# PIC32MZ1025W104132 register map
Vendor: Microchip
Registers are 32-bit, read-write, no defined reset value unless marked. A register's access mark holds for its fields unless they carry their own. Addresses are absolute, and some are shared; only a register's first bit layout is shown; [hi:lo] are bit positions; {n}, {i} and the like mark numbered series.

## ADCHS2
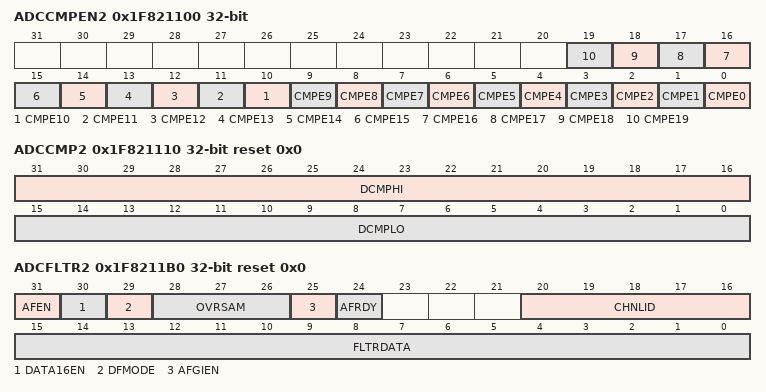
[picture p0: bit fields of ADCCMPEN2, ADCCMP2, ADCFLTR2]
0x1F821100 ADCCMPEN2 — (power-on value ------------xxxx0000000000000000)
  [n] CMPE{n} (n=0..19)
0x1F821110 ADCCMP2 reset 0x0
  [31:16] DCMPHI, [15:0] DCMPLO
0x1F8211B0 ADCFLTR2 reset 0x0
  [31] AFEN, [30] DATA16EN, [29] DFMODE, [28:26] OVRSAM, [25] AFGIEN, [24] AFRDY ro, [20:16] CHNLID, [15:0] FLTRDATA ro

## CAN1
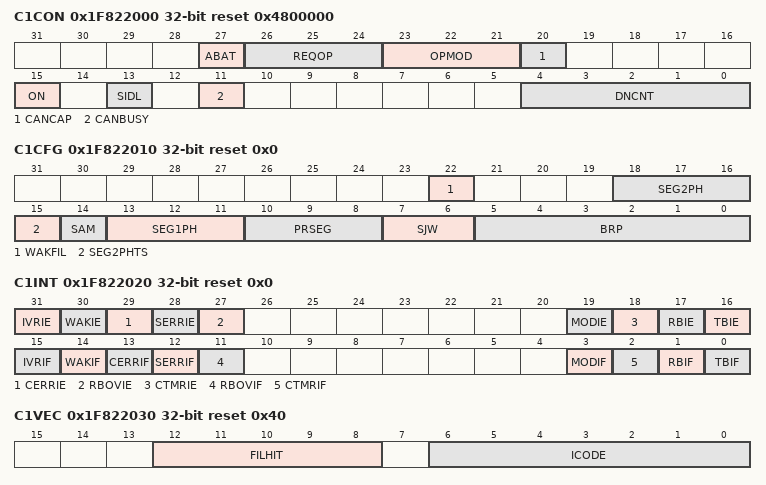
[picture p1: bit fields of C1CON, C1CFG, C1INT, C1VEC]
0x1F822000 C1CON reset 0x4800000
  [27] ABAT — (can only be set)
  [26:24] REQOP
  [23:21] OPMOD ro
  [20] CANCAP
  [15] ON
  [13] SIDL
  [11] CANBUSY ro
  [4:0] DNCNT
0x1F822010 C1CFG reset 0x0
  [22] WAKFIL, [18:16] SEG2PH, [15] SEG2PHTS, [14] SAM, [13:11] SEG1PH, [10:8] PRSEG, [7:6] SJW, [5:0] BRP
0x1F822020 C1INT reset 0x0
  [31] IVRIE, [30] WAKIE, [29] CERRIE, [28] SERRIE, [27] RBOVIE, [19] MODIE, [18] CTMRIE, [17] RBIE, [16] TBIE, [15] IVRIF, [14] WAKIF, [13] CERRIF, [12] SERRIF, [11] RBOVIF, [3] MODIF, [2] CTMRIF, [1] RBIF, [0] TBIF
0x1F822030 C1VEC ro reset 0x40
  [12:8] FILHIT, [6:0] ICODE
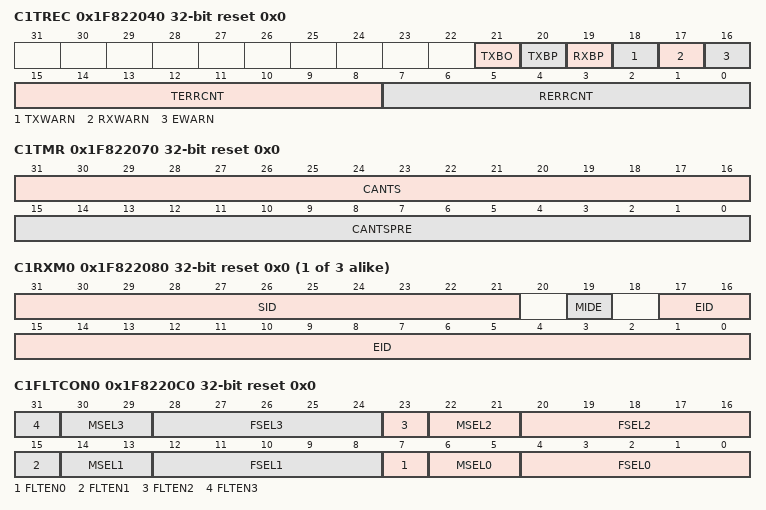
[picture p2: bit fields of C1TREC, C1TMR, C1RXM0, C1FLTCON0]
0x1F822040 C1TREC ro reset 0x0
  [21] TXBO, [20] TXBP, [19] RXBP, [18] TXWARN, [17] RXWARN, [16] EWARN, [15:8] TERRCNT, [7:0] RERRCNT
0x1F822050 C1FSTAT ro reset 0x0
  [31:0] FIFOIP
0x1F822060 C1RXOVF ro reset 0x0
  [31:0] RXOVF
0x1F822070 C1TMR reset 0x0
  [31:16] CANTS, [15:0] CANTSPRE
{0x1F822080+0x10*i} C1RXM{i} reset 0x0 (i=0..2)
  [31:21] SID, [19] MIDE, [17:0] EID
0x1F8220C0 C1FLTCON0 reset 0x0
  [8n+7] FLTEN{n} (n=0..3), [8n+6:8n+5] MSEL{n} (n=0..3), [8n+4:8n] FSEL{n} (n=0..3)
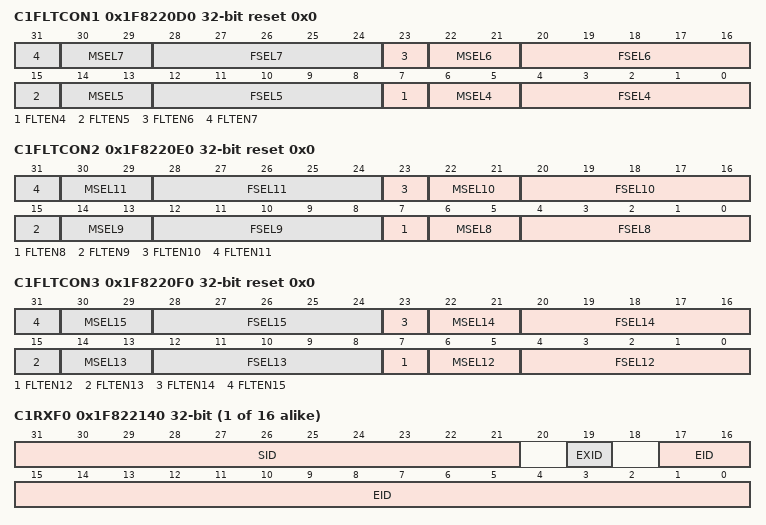
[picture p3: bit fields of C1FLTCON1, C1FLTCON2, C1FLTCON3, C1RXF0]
0x1F8220D0 C1FLTCON1 reset 0x0
  [8n-25] FLTEN{n} (n=4..7), [8n-26:8n-27] MSEL{n} (n=4..7), [8n-28:8n-32] FSEL{n} (n=4..7)
0x1F8220E0 C1FLTCON2 reset 0x0
  [8n-57] FLTEN{n} (n=8..11), [8n-58:8n-59] MSEL{n} (n=8..11), [8n-60:8n-64] FSEL{n} (n=8..11)
0x1F8220F0 C1FLTCON3 reset 0x0
  [8n-89] FLTEN{n} (n=12..15), [8n-90:8n-91] MSEL{n} (n=12..15), [8n-92:8n-96] FSEL{n} (n=12..15)
{0x1F822140+0x10*i} C1RXF{i} (i=0..15) — (power-on value xxxxxxxxxxx0x0xxxxxxxxxxxxxxxxxx)
  [31:21] SID, [19] EXID, [17:0] EID
0x1F822340 C1FIFOBA reset 0x0
  [31:2] FIFOBA
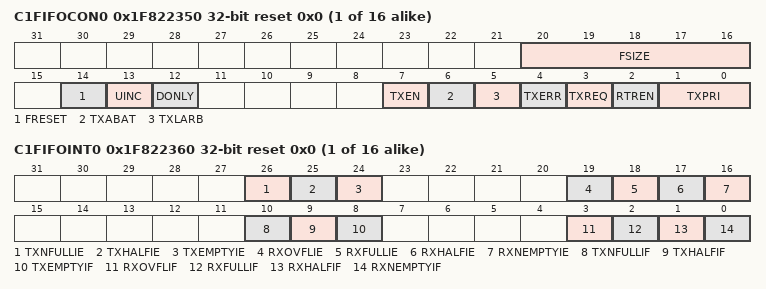
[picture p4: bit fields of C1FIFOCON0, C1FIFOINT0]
{0x1F822350+0x40*i} C1FIFOCON{i} reset 0x0 (i=0..15)
  [20:16] FSIZE, [14] FRESET, [13] UINC, [12] DONLY, [7] TXEN, [6] TXABAT, [5] TXLARB, [4] TXERR, [3] TXREQ, [2] RTREN, [1:0] TXPRI
{0x1F822360+0x40*i} C1FIFOINT{i} reset 0x0 (i=0..15)
  [26] TXNFULLIE, [25] TXHALFIE, [24] TXEMPTYIE, [19] RXOVFLIE, [18] RXFULLIE, [17] RXHALFIE, [16] RXNEMPTYIE, [10] TXNFULLIF ro, [9] TXHALFIF ro, [8] TXEMPTYIF ro, [3] RXOVFLIF, [2] RXFULLIF ro, [1] RXHALFIF ro, [0] RXNEMPTYIF ro
{0x1F822370+0x40*i} C1FIFOUA{i} ro (i=0..15) — (power-on value xxxxxxxxxxxxxxxxxxxxxxxxxxxxxx00)
  [31:2] FIFOUA
{0x1F822380+0x40*i} C1FIFOCI{i} ro reset 0x0 (i=0..15)
  [4:0] CFIFOCI

## CVD
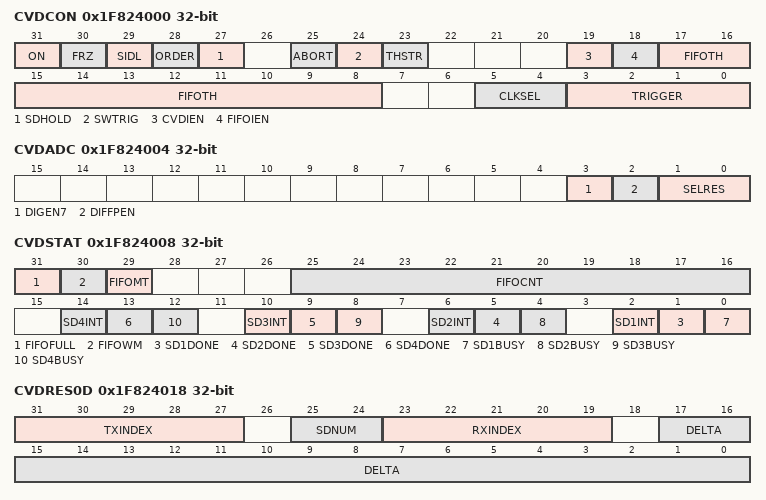
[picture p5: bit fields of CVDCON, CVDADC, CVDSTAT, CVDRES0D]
0x1F824000 CVDCON — (power-on value xxxxx-xxx---xxxxxxxxxxxx--xxxxxx)
  [31] ON, [30] FRZ, [29] SIDL, [28] ORDER, [27] SDHOLD, [25] ABORT, [24] SWTRIG, [23] THSTR, [19] CVDIEN, [18] FIFOIEN, [17:8] FIFOTH, [5:4] CLKSEL, [3:0] TRIGGER
0x1F824004 CVDADC — (power-on value ----------------------------xxxx)
  [3] DIGEN7, [2] DIFFPEN, [1:0] SELRES
0x1F824008 CVDSTAT — (power-on value xxx---xxxxxxxxxx-----------x-xxx)
  [31] FIFOFULL, [30] FIFOWM, [29] FIFOMT, [25:16] FIFOCNT, [4n-2] SD{n}INT (n=1..4), [4n-3] SD{n}DONE (n=1..4), [4n-4] SD{n}BUSY (n=1..4)
0x1F824010 CVDRES0H — (power-on value --------xxxxxxxxxxxxxxxxxxxxxxxx)
  [23:0] POS
0x1F824014 CVDRES0L — (power-on value --------xxxxxxxxxxxxxxxxxxxxxxxx)
  [23:0] NEG
0x1F824018 CVDRES0D — (power-on value xxxxx-xxxxxxx-xxxxxxxxxxxxxxxxxx)
  [31:27] TXINDEX, [25:24] SDNUM, [23:19] RXINDEX, [17:0] DELTA
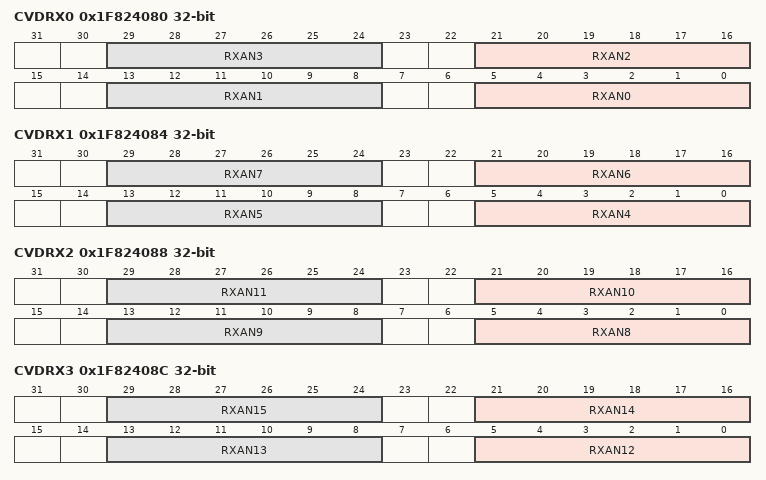
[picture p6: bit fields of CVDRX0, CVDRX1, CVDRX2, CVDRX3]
0x1F824080 CVDRX0 — (power-on value --xxxxxx--xxxxxx--xxxxxx--xxxxxx)
  [8n+5:8n] RXAN{n} (n=0..3)
0x1F824084 CVDRX1 — (power-on value --xxxxxx--xxxxxx--xxxxxx--xxxxxx)
  [8n-27:8n-32] RXAN{n} (n=4..7)
0x1F824088 CVDRX2 — (power-on value --xxxxxx--xxxxxx--xxxxxx--xxxxxx)
  [8n-59:8n-64] RXAN{n} (n=8..11)
0x1F82408C CVDRX3 — (power-on value --xxxxxx--xxxxxx--xxxxxx--xxxxxx)
  [8n-91:8n-96] RXAN{n} (n=12..15)
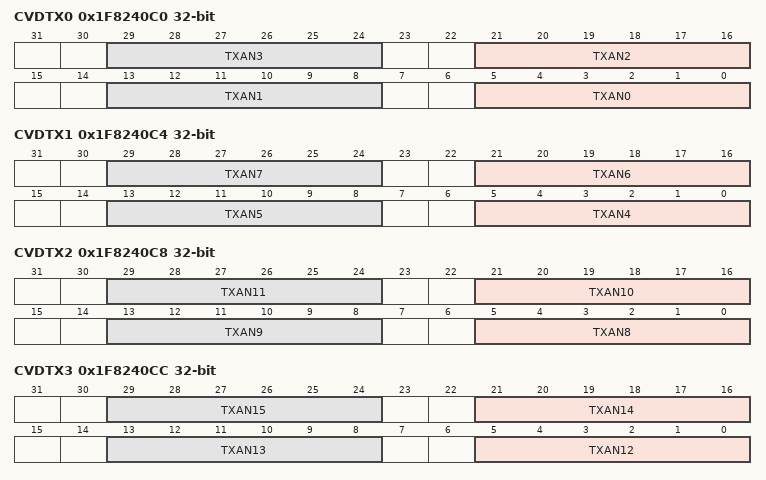
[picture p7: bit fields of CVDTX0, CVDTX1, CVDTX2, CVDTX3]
0x1F8240C0 CVDTX0 — (power-on value --xxxxxx--xxxxxx--xxxxxx--xxxxxx)
  [8n+5:8n] TXAN{n} (n=0..3)
0x1F8240C4 CVDTX1 — (power-on value --xxxxxx--xxxxxx--xxxxxx--xxxxxx)
  [8n-27:8n-32] TXAN{n} (n=4..7)
0x1F8240C8 CVDTX2 — (power-on value --xxxxxx--xxxxxx--xxxxxx--xxxxxx)
  [8n-59:8n-64] TXAN{n} (n=8..11)
0x1F8240CC CVDTX3 — (power-on value --xxxxxx--xxxxxx--xxxxxx--xxxxxx)
  [8n-91:8n-96] TXAN{n} (n=12..15)
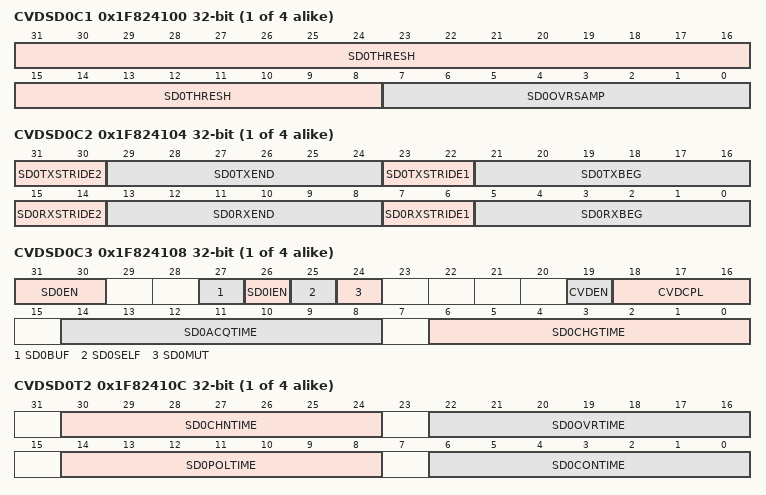
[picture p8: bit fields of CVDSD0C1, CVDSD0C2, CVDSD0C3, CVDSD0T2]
{0x1F824100+0x10*i} CVDSD{i}C1 (i=0..3) — (power-on value xxxxxxxxxxxxxxxxxxxxxxxxxxxxxxxx)
  [31:8] SD{i}THRESH, [7:0] SD{i}OVRSAMP
{0x1F824104+0x10*i} CVDSD{i}C2 (i=0..3) — (power-on value xxxxxxxxxxxxxxxxxxxxxxxxxxxxxxxx)
  [31:30] SD{i}TXSTRIDE2, [29:24] SD{i}TXEND, [23:22] SD{i}TXSTRIDE1, [21:16] SD{i}TXBEG, [15:14] SD{i}RXSTRIDE2, [13:8] SD{i}RXEND, [7:6] SD{i}RXSTRIDE1, [5:0] SD{i}RXBEG
{0x1F824108+0x10*i} CVDSD{i}C3 (i=0..3) — (power-on value xx--xxxx----xxxx-xxxxxxx-xxxxxxx)
  [31:30] SD{i}EN, [27] SD{i}BUF, [26] SD{i}IEN, [25] SD{i}SELF, [24] SD{i}MUT, [19] CVDEN, [18:16] CVDCPL, [14:8] SD{i}ACQTIME, [6:0] SD{i}CHGTIME
{0x1F82410C+0x10*i} CVDSD{i}T2 (i=0..3) — (power-on value -xxxxxxx-xxxxxxx-xxxxxxx-xxxxxxx)
  [30:24] SD{i}CHNTIME, [22:16] SD{i}OVRTIME, [14:8] SD{i}POLTIME, [6:0] SD{i}CONTIME
